# nrf54h20_enga_secure register map
Vendor: Nordic Semiconductor; Series: nRF54h; File version: 1
CPU: CM33 r0p4, little endian, MPU, no FPU, 3 interrupt priority bits, 480 interrupts, 4 SAU regions
Registers are 32-bit, read-write, reset 0x0 unless marked. A register's access mark holds for its fields unless they carry their own. Offsets are from the block's base; [hi:lo] are bit positions; lines under a group give offsets from that group; {n}, {i} and the like mark numbered series; 'fields as' and 'values as' point back to an identical list.

## TAMPC_S — Tamper controller
Base 0x51016000
0x100 EVENTS_TAMPER — Tamper controller detected an error.
  [0] EVENTS_TAMPER
    0=NotGenerated (Event not generated); 1=Generated (Event generated)
0x300 INTEN — Enable or disable interrupt
  [0] TAMPER — Enable or disable interrupt for event TAMPER
    0=Disabled; 1=Enabled
0x304 INTENSET — Enable interrupt
  [0] TAMPER — Write '1' to enable interrupt for event TAMPER
    on read: 0=Disabled (Read: Disabled); 1=Enabled (Read: Enabled) | on write: 1=Set (Enable)
0x308 INTENCLR — Disable interrupt
  [0] TAMPER — Write '1' to disable interrupt for event TAMPER
    on read: 0=Disabled (Read: Disabled); 1=Enabled (Read: Enabled) | on write: 1=Clear (Disable)
0x30C INTPEND ro — Pending interrupts
  [0] TAMPER — Read pending status of interrupt for event TAMPER
    on read: 0=NotPending (Read: Not pending); 1=Pending (Read: Pending)
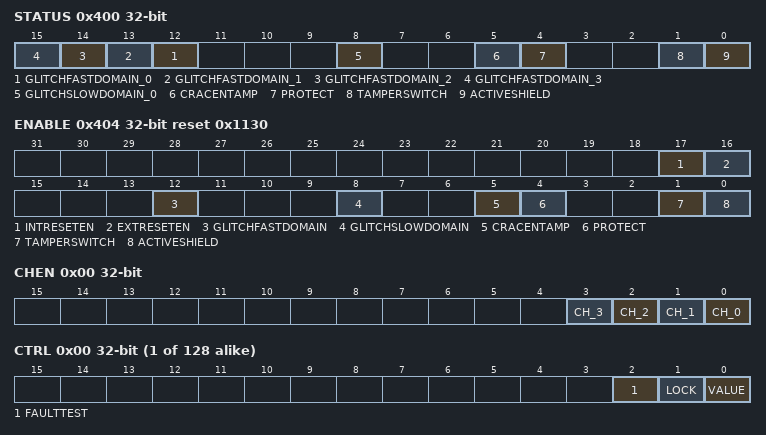
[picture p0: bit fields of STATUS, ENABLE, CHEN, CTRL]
0x400 STATUS write-1-clears — The tamper controller status.
  [all] fields
    0=NotDetected; 1=Detected
  [n+12] GLITCHFASTDOMAIN_{n} (n=0..3) — Fast domain glitch detector {n} detected an error.
  [8] GLITCHSLOWDOMAIN_0 — Slow domain glitch detector 0 detected an error.
  [5] CRACENTAMP — CRACEN detected an error.
  [4] PROTECT — Error detected for the protected signals.
  [1] TAMPERSWITCH — External tamper switch detector detected an error.
  [0] ACTIVESHIELD — Active shield detector detected an error.
0x404 ENABLE reset 0x1130 — Enable the tamper detectors.
  [all] fields
    0=Disabled; 1=Enabled
  [17] INTRESETEN — Trigger a reset when tamper is detected by the glitch detectors, signal protector or CRACEN tamper detector.
  [16] EXTRESETEN — Trigger a reset when tamper is detected by the active shield or tamper switch detector.
  [12] GLITCHFASTDOMAIN — Enable fast domain glitch detectors.
  [8] GLITCHSLOWDOMAIN — Enable slow domain glitch detectors.
  [5] CRACENTAMP — Enable tamper detector from CRACEN.
  [4] PROTECT — Enable the detector for the protected signals.
  [1] TAMPERSWITCH — Enable external tamper switch detector.
  [0] ACTIVESHIELD — Enable active shield detector.
0x408 ACTIVESHIELD group — Unspecified
  0x00 CHEN — Active shield detector channel enable register.
    [all] fields
      0=Disabled (Disable channel.); 1=Enabled (Enable channel.)
    [n] CH_{n} (n=0..3) — Enable or disable active shield channel {n}.
0x40C GLITCH group — Unspecified
  0x00 CONFIGSLOWDOMAIN — Configuration for slow domain glitch detectors.
    [3:0] EXTRADELAY — Extra delay configuration.
  0x04 CONFIGFASTDOMAIN — Configuration for fast domain glitch detectors.
    [3:0] EXTRADELAY — Extra delay configuration.
0x500 PROTECT group — Unspecified
  {0x0+8j} FEATURE[{j}] (j=0..127) group — Unspecified
    0x00 CTRL — Description cluster: Control register for protect feature n.
      [2] FAULTTEST — Injects a fault in the protected signal.
        0=NoOperation; 1=Trigger fault
      [1] LOCK write-once write-1-sets — Lock this register to prevent changes.
        0=Disabled (Lock disabled.); 1=Enabled (Lock enabled.)
      [0] VALUE — Set value of protect feature n.
        0=Low (Signal is logic 0.); 1=High (Signal is logic 1.)
    0x04 STATUS write-1-clears — Description cluster: Status register for protect feature n.
      [0] ERROR — Error detection status.
        0=No error detected; 1=Error detected
  0x00 STRUCT0 group (alternate view of FEATURE[*]) — Unspecified
    {0x0+0x20*k} DOMAIN[{k}] (k=0..15) group — Unspecified
      0x00 DBGEN group — Unspecified
        0x00 CTRL — Description cluster: Control register for invasive (halting) debug enable for the local debug components within domain n.
          [2] FAULTTEST — Injects a fault in the protected signal.
            0=NoOperation; 1=Trigger fault
          [1] LOCK write-once write-1-sets — Lock this register to prevent changes.
            0=Disabled (Lock disabled.); 1=Enabled (Lock enabled.)
          [0] VALUE — Set value of dbgen signal.
            0=Low (Signal is logic 0.); 1=High (Signal is logic 1.)
        0x04 STATUS write-1-clears — Description cluster: Status register for invasive (halting) debug enable for domain n.
          fields as PROTECT.FEATURE[0].STATUS
      0x08 NIDEN group — Unspecified
        0x00 CTRL — Description cluster: Control register for non-invasive debug enable for the local debug components within domain n.
          [2] FAULTTEST — Injects a fault in the protected signal.
            0=NoOperation; 1=Trigger fault
          [1] LOCK write-once write-1-sets — Lock this register to prevent changes.
            0=Disabled (Lock disabled.); 1=Enabled (Lock enabled.)
          [0] VALUE — Set value of niden signal.
            0=Low (Signal is logic 0.); 1=High (Signal is logic 1.)
        0x04 STATUS write-1-clears — Description cluster: Status register for non-invasive debug enable for domain n.
          fields as PROTECT.FEATURE[0].STATUS
      0x10 SPIDEN group — Unspecified
        0x00 CTRL — Description cluster: Control register for secure priviliged invasive (halting) debug enable for the local debug components within domain n.
          [2] FAULTTEST — Injects a fault in the protected signal.
            0=NoOperation; 1=Trigger fault
          [1] LOCK write-once write-1-sets — Lock this register to prevent changes.
            0=Disabled (Lock disabled.); 1=Enabled (Lock enabled.)
          [0] VALUE — Set value of spiden signal.
            0=Low (Signal is logic 0.); 1=High (Signal is logic 1.)
        0x04 STATUS write-1-clears — Description cluster: Status register for secure priviliged invasive (halting) debug enable for domain n.
          fields as PROTECT.FEATURE[0].STATUS
      0x18 SPNIDEN group — Unspecified
        0x00 CTRL — Description cluster: Control register for secure priviliged non-invasive debug enable for the local debug components within domain n.
          [2] FAULTTEST — Injects a fault in the protected signal.
            0=NoOperation; 1=Trigger fault
          [1] LOCK write-once write-1-sets — Lock this register to prevent changes.
            0=Disabled (Lock disabled.); 1=Enabled (Lock enabled.)
          [0] VALUE — Set value of spniden signal.
            0=Low (Signal is logic 0.); 1=High (Signal is logic 1.)
        0x04 STATUS write-1-clears — Description cluster: Status register for secure priviliged non-invasive debug enable for domain n.
          fields as PROTECT.FEATURE[0].STATUS
    {0x200+0x10*k} AP[{k}] (k=0..15) group — Unspecified
      0x00 DBGEN group — Unspecified
        0x00 CTRL — Description cluster: Control register to enable invasive (halting) debug in domain n's access port.
          fields as PROTECT.STRUCT0.DOMAIN[0].DBGEN.CTRL
        0x04 STATUS write-1-clears — Description cluster: Status register for invasive (halting) debug enable for domain n's access port.
          fields as PROTECT.FEATURE[0].STATUS
      0x08 SPIDEN group — Unspecified
        0x00 CTRL — Description cluster: Control register to enable secure priviliged invasive (halting) debug in domain n's access port.
          fields as PROTECT.STRUCT0.DOMAIN[0].SPIDEN.CTRL
        0x04 STATUS write-1-clears — Description cluster: Status register for secure priviliged invasive (halting) debug enable for domain n's access port.
          fields as PROTECT.FEATURE[0].STATUS
    0x300 CORESIGHT group — Unspecified
      0x00 DEVICEEN group — Unspecified
        0x00 CTRL — Controls the access port to the trace and debug domain, part of CoreSight configuration registers.
          [2] FAULTTEST — Injects a fault in the protected signal.
            0=NoOperation; 1=Trigger fault
          [1] LOCK write-once write-1-sets — Lock this register to prevent changes.
            0=Disabled (Lock disabled.); 1=Enabled (Lock enabled.)
          [0] VALUE — Set value of deviceen signal.
            0=Low (Signal is logic 0.); 1=High (Signal is logic 1.)
        0x04 STATUS write-1-clears — Status register for the trace and debug domain access port.
          fields as PROTECT.FEATURE[0].STATUS
      0x08 DBGEN group — Unspecified
        0x00 CTRL — Control register for invasive (halting) debug enable for the Coresight domain.
          fields as PROTECT.STRUCT0.DOMAIN[0].DBGEN.CTRL
        0x04 STATUS write-1-clears — Status register for invasive (halting) debug enable for Coresight domain.
          fields as PROTECT.FEATURE[0].STATUS
      0x10 NIDEN group — Unspecified
        0x00 CTRL — Control register for non-invasive debug enable for the Coresight domain.
          fields as PROTECT.STRUCT0.DOMAIN[0].NIDEN.CTRL
        0x04 STATUS write-1-clears — Status register for non-invasive debug enable for Coresight domain.
          fields as PROTECT.FEATURE[0].STATUS
      0x18 SPIDEN group — Unspecified
        0x00 CTRL — Control register for secure priviliged invasive (halting) debug enable for the Coresight domain.
          fields as PROTECT.STRUCT0.DOMAIN[0].SPIDEN.CTRL
        0x04 STATUS write-1-clears — Status register for secure priviliged invasive (halting) debug enable for Coresight domain.
          fields as PROTECT.FEATURE[0].STATUS
      0x20 SPNIDEN group — Unspecified
        0x00 CTRL — Control register for secure priviliged non-invasive debug enable for the Coresight domain.
          fields as PROTECT.STRUCT0.DOMAIN[0].SPNIDEN.CTRL
        0x04 STATUS write-1-clears — Status register for secure priviliged non-invasive debug enable for Coresight domain.
          fields as PROTECT.FEATURE[0].STATUS
    0x330 CRACEN group — Unspecified
      0x00 AESDISABLECM group — Unspecified
        0x00 CTRL — Control register to disable AES DPA counter-measures in CRACEN.
          [2] FAULTTEST — Injects a fault in the protected signal.
            0=NoOperation; 1=Trigger fault
          [1] LOCK write-once write-1-sets — Lock this register to prevent changes.
            0=Disabled (Lock disabled.); 1=Enabled (Lock enabled.)
          [0] VALUE — Set value of AES DPA counter-measures disable signal.
            0=Low (Signal is logic 0.); 1=High (Signal is logic 1.)
        0x04 STATUS write-1-clears — Status register for the AES DPA counter-measures disable signal in CRACEN.
          fields as PROTECT.FEATURE[0].STATUS
      0x08 SM4DISABLECM group — Unspecified
        0x00 CTRL — Control register to disable SM4 in CRACEN.
          [2] FAULTTEST — Injects a fault in the protected signal.
            0=NoOperation; 1=Trigger fault
          [1] LOCK write-once write-1-sets — Lock this register to prevent changes.
            0=Disabled (Lock disabled.); 1=Enabled (Lock enabled.)
          [0] VALUE — Set value of SM4 DPA counter-measures disable signal.
            0=Low (Signal is logic 0.); 1=High (Signal is logic 1.)
        0x04 STATUS write-1-clears — Status register for the SM4 DPA counter-measures disable signal in CRACEN.
          fields as PROTECT.FEATURE[0].STATUS
      0x10 PKDISABLECM group — Unspecified
        0x00 CTRL — Control register to disable PK engine DPA counter-measures in CRACEN.
          [2] FAULTTEST — Injects a fault in the protected signal.
            0=NoOperation; 1=Trigger fault
          [1] LOCK write-once write-1-sets — Lock this register to prevent changes.
            0=Disabled (Lock disabled.); 1=Enabled (Lock enabled.)
          [0] VALUE — Set value of PK engine DPA counter-measures disable signal.
            0=Low (Signal is logic 0.); 1=High (Signal is logic 1.)
        0x04 STATUS write-1-clears — Status register for the PK engine DPA counter-measures disable signal in CRACEN.
          fields as PROTECT.FEATURE[0].STATUS
    0x3E8 WARMBOOT group — Unspecified
      0x00 UNRETIDLE group — Unspecified
        0x00 CTRL — Control register to enable warm boot from unretained idle mode.
          [2] FAULTTEST — Injects a fault in the protected signal.
            0=NoOperation; 1=Trigger fault
          [1] LOCK write-once write-1-sets — Lock this register to prevent changes.
            0=Disabled (Lock disabled.); 1=Enabled (Lock enabled.)
          [0] VALUE — Set value of warm boot unretained idle signal.
            0=Low (Signal is logic 0.); 1=High (Signal is logic 1.)
        0x04 STATUS write-1-clears — Status register for the warm boot unretained idle signal.
          fields as PROTECT.FEATURE[0].STATUS
      0x08 SYSTEMOFF group — Unspecified
        0x00 CTRL — Control register to enable warm boot from system off mode.
          [2] FAULTTEST — Injects a fault in the protected signal.
            0=NoOperation; 1=Trigger fault
          [1] LOCK write-once write-1-sets — Lock this register to prevent changes.
            0=Disabled (Lock disabled.); 1=Enabled (Lock enabled.)
          [0] VALUE — Set value of the warm boot system off signal.
            0=Low (Signal is logic 0.); 1=High (Signal is logic 1.)
        0x04 STATUS write-1-clears — Status register for the warm boot system off signal.
          fields as PROTECT.FEATURE[0].STATUS
    0x3F8 DFT group — Unspecified
      0x00 ENABLE group — Unspecified
        0x00 CTRL reset 0x8 — Control register to enable DFT mode.
          [3] RDCPROTECT — Write protection of VALUE bit.
            0=Unprotected (VALUE field is unprotected and can be set.); 1=Protected (VALUE field is protected and can not be written.)
          [2] FAULTTEST — Injects a fault in the protected signal.
            0=NoOperation; 1=Trigger fault
          [1] LOCK write-once write-1-sets — Lock this register to prevent changes.
            0=Disabled (Lock disabled.); 1=Enabled (Lock enabled.)
          [0] VALUE — Set value of dft_enable signal.
            0=Low (Signal is logic 0.); 1=High (Signal is logic 1.)
        0x04 STATUS write-1-clears — Status register for enable DFT mode.
          fields as PROTECT.FEATURE[0].STATUS
